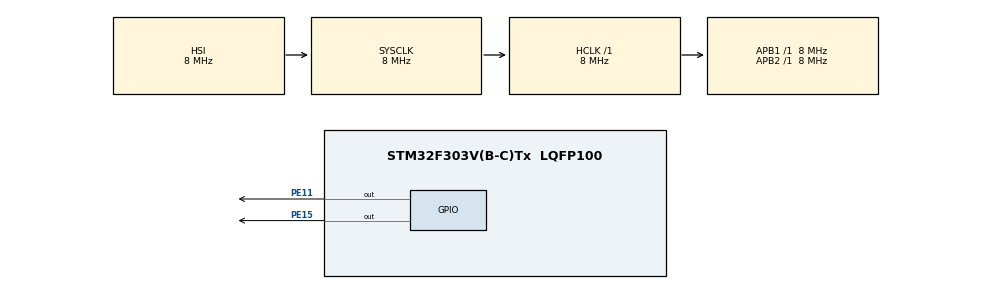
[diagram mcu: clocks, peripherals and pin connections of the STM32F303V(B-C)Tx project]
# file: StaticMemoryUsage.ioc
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FREERTOS.Tasks01=defaultTask,24,128,StartDefaultTask,Default,NULL,Static,defaultTaskBuffer,defaultTaskControlBlock;LedController,8,128,ledController,Default,NULL,Static,LedControllerBuffer,LedControllerControlBlock
Mcu.Family=STM32F3
Mcu.Name=STM32F303V(B-C)Tx
Mcu.Package=LQFP100
NVIC.PriorityGroup=NVIC_PRIORITYGROUP_4
NVIC.TIM1_UP_TIM16_IRQn=true\:0\:0\:false\:false\:true\:false\:false\:true
NVIC.TimeBase=TIM1_UP_TIM16_IRQn
NVIC.TimeBaseIP=TIM1
PE11.Signal=GPIO_Output
PE15.Signal=GPIO_Output
ProjectManager.HeapSize=0x200
ProjectManager.StackSize=0x400
ProjectManager.TargetToolchain=MDK-ARM V5.27
RCC.AHBFreq_Value=8000000
RCC.APB1Freq_Value=8000000
RCC.APB2Freq_Value=8000000
RCC.CortexFreq_Value=8000000
RCC.HSE_VALUE=8000000
RCC.HSI_VALUE=8000000
RCC.LSE_VALUE=32768
RCC.SYSCLKFreq_VALUE=8000000
VP_FREERTOS_VS_CMSIS_V2.Mode=CMSIS_V2
VP_SYS_VS_tim1.Mode=TIM1
board=custom

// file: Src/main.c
/* USER CODE BEGIN Header */
/**
  ******************************************************************************
  * @file           : main.c
  * @brief          : Main program body
  ******************************************************************************
  * @attention
  *
  * <h2><center>&copy; Copyright (c) 2020 STMicroelectronics.
  * All rights reserved.</center></h2>
  *
  * This software component is licensed by ST under Ultimate Liberty license
  * SLA0044, the "License"; You may not use this file except in compliance with
  * the License. You may obtain a copy of the License at:
  *                             www.st.com/SLA0044
  *
  ******************************************************************************
  */
/* USER CODE END Header */

#include "main.h"
#include "cmsis_os.h"
#include "stm32f3xx.h"                  // Device header

typedef StaticTask_t osStaticThreadDef_t;
osThreadId_t defaultTaskHandle;
uint32_t defaultTaskBuffer[ 128 ];
osStaticThreadDef_t defaultTaskControlBlock;
osThreadId_t LedControllerHandle;
uint32_t LedControllerBuffer[ 128 ];
osStaticThreadDef_t LedControllerControlBlock;

void SystemClock_Config(void);
static void MX_GPIO_Init(void);
void StartDefaultTask(void *argument);
void ledController(void *argument);

int main(void)
{

  /* MCU Configuration--------------------------------------------------------*/

  /* Reset of all peripherals, Initializes the Flash interface and the Systick. */
  HAL_Init();

  /* Configure the system clock */
  SystemClock_Config();

  /* Initialize all configured peripherals */
  MX_GPIO_Init();
  /* USER CODE BEGIN 2 */
  vTraceEnable(TRC_INIT);
  /* USER CODE END 2 */

  osKernelInitialize();

  /* Create the thread(s) */
  /* definition and creation of defaultTask */
  const osThreadAttr_t defaultTask_attributes = {
    .name = "defaultTask",
    .stack_mem = &defaultTaskBuffer[0],
    .stack_size = sizeof(defaultTaskBuffer),
    .cb_mem = &defaultTaskControlBlock,
    .cb_size = sizeof(defaultTaskControlBlock),
    .priority = (osPriority_t) osPriorityNormal,
  };
  defaultTaskHandle = osThreadNew(StartDefaultTask, NULL, &defaultTask_attributes);

  /* definition and creation of LedController */
  const osThreadAttr_t LedController_attributes = {
    .name = "LedController",
    .stack_mem = &LedControllerBuffer[0],
    .stack_size = sizeof(LedControllerBuffer),
    .cb_mem = &LedControllerControlBlock,
    .cb_size = sizeof(LedControllerControlBlock),
    .priority = (osPriority_t) osPriorityLow,
  };
  LedControllerHandle = osThreadNew(ledController, NULL, &LedController_attributes);

  /* Start scheduler */
  osKernelStart();

  /* We should never get here as control is now taken by the scheduler */

  /* Infinite loop */
  while (1)
  {

  }
}

void SystemClock_Config(void)
{
  RCC_OscInitTypeDef RCC_OscInitStruct = {0};
  RCC_ClkInitTypeDef RCC_ClkInitStruct = {0};

  /** Initializes the CPU, AHB and APB busses clocks
  */
  RCC_OscInitStruct.OscillatorType = RCC_OSCILLATORTYPE_HSI;
  RCC_OscInitStruct.HSIState = RCC_HSI_ON;
  RCC_OscInitStruct.HSICalibrationValue = RCC_HSICALIBRATION_DEFAULT;
  RCC_OscInitStruct.PLL.PLLState = RCC_PLL_NONE;
  if (HAL_RCC_OscConfig(&RCC_OscInitStruct) != HAL_OK)
  {
    Error_Handler();
  }
  /** Initializes the CPU, AHB and APB busses clocks
  */
  RCC_ClkInitStruct.ClockType = RCC_CLOCKTYPE_HCLK|RCC_CLOCKTYPE_SYSCLK
                              |RCC_CLOCKTYPE_PCLK1|RCC_CLOCKTYPE_PCLK2;
  RCC_ClkInitStruct.SYSCLKSource = RCC_SYSCLKSOURCE_HSI;
  RCC_ClkInitStruct.AHBCLKDivider = RCC_SYSCLK_DIV1;
  RCC_ClkInitStruct.APB1CLKDivider = RCC_HCLK_DIV1;
  RCC_ClkInitStruct.APB2CLKDivider = RCC_HCLK_DIV1;

  if (HAL_RCC_ClockConfig(&RCC_ClkInitStruct, FLASH_LATENCY_0) != HAL_OK)
  {
    Error_Handler();
  }
}

static void MX_GPIO_Init(void)
{
  GPIO_InitTypeDef GPIO_InitStruct = {0};

  /* GPIO Ports Clock Enable */
  __HAL_RCC_GPIOE_CLK_ENABLE();

  /*Configure GPIO pin Output Level */
  HAL_GPIO_WritePin(GPIOE, GPIO_PIN_11|GPIO_PIN_15, GPIO_PIN_RESET);

  /*Configure GPIO pins : PE11 PE15 */
  GPIO_InitStruct.Pin = GPIO_PIN_11|GPIO_PIN_15;
  GPIO_InitStruct.Mode = GPIO_MODE_OUTPUT_PP;
  GPIO_InitStruct.Pull = GPIO_NOPULL;
  GPIO_InitStruct.Speed = GPIO_SPEED_FREQ_LOW;
  HAL_GPIO_Init(GPIOE, &GPIO_InitStruct);

}

void StartDefaultTask(void *argument)
{
  for(;;)
  {
    osDelay(1);
  }
}

void ledController(void *argument)
{
  /* USER CODE BEGIN ledController */
  /* Infinite loop */
  for(;;)
  {
		HAL_GPIO_TogglePin(GPIOE, GPIO_PIN_11 | GPIO_PIN_15);
    osDelay(1000);
  }
  /* USER CODE END ledController */
}

void HAL_TIM_PeriodElapsedCallback(TIM_HandleTypeDef *htim)
{
  if (htim->Instance == TIM1) {
    HAL_IncTick();
  }
}

void Error_Handler(void)
{
}

/************************ (C) COPYRIGHT STMicroelectronics *****END OF FILE****/
